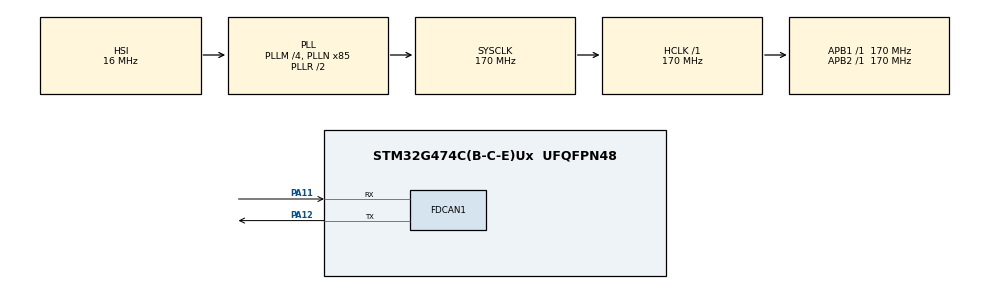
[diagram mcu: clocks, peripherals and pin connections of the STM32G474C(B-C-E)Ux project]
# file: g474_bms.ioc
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FDCAN1.CalculateBaudRateNominal=1000000
FDCAN1.CalculateTimeBitNominal=1000
FDCAN1.CalculateTimeQuantumNominal=100.0
FDCAN1.NominalPrescaler=17
FDCAN1.NominalTimeSeg1=8
Mcu.Family=STM32G4
Mcu.Name=STM32G474C(B-C-E)Ux
Mcu.Package=UFQFPN48
NVIC.FDCAN1_IT0_IRQn=true\:0\:0\:false\:false\:true\:true\:true\:true
NVIC.PriorityGroup=NVIC_PRIORITYGROUP_4
PA11.Mode=FDCAN_Activate
PA11.Signal=FDCAN1_RX
PA12.Mode=FDCAN_Activate
PA12.Signal=FDCAN1_TX
PA13.Mode=Serial_Wire
PA13.Signal=SYS_JTMS-SWDIO
PA14.Mode=Serial_Wire
PA14.Signal=SYS_JTCK-SWCLK
ProjectManager.HeapSize=0x200
ProjectManager.StackSize=0x400
ProjectManager.TargetToolchain=STM32CubeIDE
RCC.ADC12Freq_Value=170000000
RCC.ADC345Freq_Value=170000000
RCC.AHBFreq_Value=170000000
RCC.APB1Freq_Value=170000000
RCC.APB1TimFreq_Value=170000000
RCC.APB2Freq_Value=170000000
RCC.APB2TimFreq_Value=170000000
RCC.CortexFreq_Value=170000000
RCC.EXTERNAL_CLOCK_VALUE=12288000
RCC.HCLKFreq_Value=170000000
RCC.HSE_VALUE=8000000
RCC.HSI48_VALUE=48000000
RCC.HSI_VALUE=16000000
RCC.LSE_VALUE=32768
RCC.PLLM=RCC_PLLM_DIV4
RCC.PLLN=85
RCC.SYSCLKFreq_VALUE=170000000
RCC.SYSCLKSource=RCC_SYSCLKSOURCE_PLLCLK
RCC.USBFreq_Value=170000000
RCC.VCOOutputFreq_Value=340000000
VP_SYS_VS_DBSignals.Mode=DisableDeadBatterySignals
board=custom

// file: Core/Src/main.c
/* USER CODE BEGIN Header */
/**
  ******************************************************************************
  * @file           : main.c
  * @brief          : Main program body
  ******************************************************************************
  * @attention
  *
  * Copyright (c) 2025 STMicroelectronics.
  * All rights reserved.
  *
  * This software is licensed under terms that can be found in the LICENSE file
  * in the root directory of this software component.
  * If no LICENSE file comes with this software, it is provided AS-IS.
  *
  ******************************************************************************
  */
/* USER CODE END Header */
#include "main.h"
#include "fdcan.h"
#include "gpio.h"

/* USER CODE BEGIN Includes */
#include "bms.h"
/* USER CODE END Includes */

void SystemClock_Config(void);

/* USER CODE BEGIN 0 */
FDCAN_TxHeaderTypeDef TxHeader;
FDCAN_RxHeaderTypeDef RxHeader;
uint8_t RxData[8] ;

uint32_t TxMailbox;
uint8_t TxData[8] ;

//int datacheck = 0;
//int firsttimes = 1;

void HAL_FDCAN_RxFifo0Callback(FDCAN_HandleTypeDef *hfdcan, uint32_t RxFifo0ITs)
{
    if ((RxFifo0ITs & FDCAN_IT_RX_FIFO0_NEW_MESSAGE) != 0)
    {
        HAL_FDCAN_GetRxMessage(hfdcan, FDCAN_RX_FIFO0, &RxHeader, RxData);

        // Optional: blink LED or set a flag
    }
}
/* USER CODE END 0 */

int main(void)
{

  /* MCU Configuration--------------------------------------------------------*/

  /* Reset of all peripherals, Initializes the Flash interface and the Systick. */
  HAL_Init();

  /* Configure the system clock */
  SystemClock_Config();

  /* Initialize all configured peripherals */
  MX_GPIO_Init();
  MX_FDCAN1_Init();
  /* USER CODE BEGIN 2 */
  HAL_FDCAN_Start(&hfdcan1);
  HAL_FDCAN_ActivateNotification(&hfdcan1, FDCAN_IT_RX_FIFO0_NEW_MESSAGE, 0);

   TxHeader.IdType = FDCAN_EXTENDED_ID;
   TxHeader.DataLength = FDCAN_DLC_BYTES_8;
   TxHeader.Identifier = 0x18FF50E5;   // ID can be between Hex1 and Hex7FF (1-2047 decimal)
   TxHeader.FDFormat = FDCAN_CLASSIC_CAN;

  /* USER CODE END 2 */

  /* Infinite loop */
  /* USER CODE BEGIN WHILE */
  while (1)
  {
	  BMS_Update(&hfdcan1);
	  BatteryMsg* data = BMS_GetData();

    /* USER CODE END WHILE */

  }
}

void SystemClock_Config(void)
{
  RCC_OscInitTypeDef RCC_OscInitStruct = {0};
  RCC_ClkInitTypeDef RCC_ClkInitStruct = {0};

  /** Configure the main internal regulator output voltage
  */
  HAL_PWREx_ControlVoltageScaling(PWR_REGULATOR_VOLTAGE_SCALE1_BOOST);

  /** Initializes the RCC Oscillators according to the specified parameters
  * in the RCC_OscInitTypeDef structure.
  */
  RCC_OscInitStruct.OscillatorType = RCC_OSCILLATORTYPE_HSI;
  RCC_OscInitStruct.HSIState = RCC_HSI_ON;
  RCC_OscInitStruct.HSICalibrationValue = RCC_HSICALIBRATION_DEFAULT;
  RCC_OscInitStruct.PLL.PLLState = RCC_PLL_ON;
  RCC_OscInitStruct.PLL.PLLSource = RCC_PLLSOURCE_HSI;
  RCC_OscInitStruct.PLL.PLLM = RCC_PLLM_DIV4;
  RCC_OscInitStruct.PLL.PLLN = 85;
  RCC_OscInitStruct.PLL.PLLP = RCC_PLLP_DIV2;
  RCC_OscInitStruct.PLL.PLLQ = RCC_PLLQ_DIV2;
  RCC_OscInitStruct.PLL.PLLR = RCC_PLLR_DIV2;
  if (HAL_RCC_OscConfig(&RCC_OscInitStruct) != HAL_OK)
  {
    Error_Handler();
  }

  /** Initializes the CPU, AHB and APB buses clocks
  */
  RCC_ClkInitStruct.ClockType = RCC_CLOCKTYPE_HCLK|RCC_CLOCKTYPE_SYSCLK
                              |RCC_CLOCKTYPE_PCLK1|RCC_CLOCKTYPE_PCLK2;
  RCC_ClkInitStruct.SYSCLKSource = RCC_SYSCLKSOURCE_PLLCLK;
  RCC_ClkInitStruct.AHBCLKDivider = RCC_SYSCLK_DIV1;
  RCC_ClkInitStruct.APB1CLKDivider = RCC_HCLK_DIV1;
  RCC_ClkInitStruct.APB2CLKDivider = RCC_HCLK_DIV1;

  if (HAL_RCC_ClockConfig(&RCC_ClkInitStruct, FLASH_LATENCY_4) != HAL_OK)
  {
    Error_Handler();
  }
}

void Error_Handler(void)
{
  __disable_irq();
  while (1)
  {
  }
}
